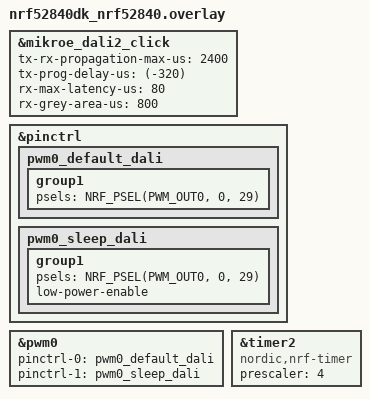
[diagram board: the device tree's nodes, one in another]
/*
 * Copyright 2025 by Markus Becker
 * SPDX-License-Identifier: Apache-2.0
 *
 * add DALI 2 Click (MIKROE-2672)
 * via Arduino UNO click shield (MIKROE-1581)
 * to Nordic nRF52840DK (pca10056)
 * DALI 2 Click
 *   DALI TX 2
 *   DALI RX 15
 * Arduino UNO click shield (slot 1)
 *   DALI TX 2 > A3
 *   DALI RX 15 > D2
 * nRF52840DK
 *   DALI TX A3 > P0.29
 *   DALI RX D2 > P1.03
 */

&mikroe_dali2_click {
	tx-rx-propagation-max-us = <2400>;
	tx-prog-delay-us = <(-320)>;
	rx-max-latency-us = <80>;
	rx-grey-area-us = <800>;
};

&pinctrl {
	pwm0_default_dali: pwm0_default_dali {
		group1 {
			psels = <NRF_PSEL(PWM_OUT0, 0, 29)>; // mikrobus_header_1 2
		};
	};

	pwm0_sleep_dali: pwm0_sleep_dali {
		group1 {
			psels = <NRF_PSEL(PWM_OUT0, 0, 29)>; // mikrobus_header_1 2
			low-power-enable;
		};
	};
};

&pwm0 {
	status = "okay";
	pinctrl-0 = <&pwm0_default_dali>;
	pinctrl-1 = <&pwm0_sleep_dali>;
	pinctrl-names = "default", "sleep";
};

&timer2 {
	compatible = "nordic,nrf-timer";
	status = "okay";
	prescaler = <4>;
};
